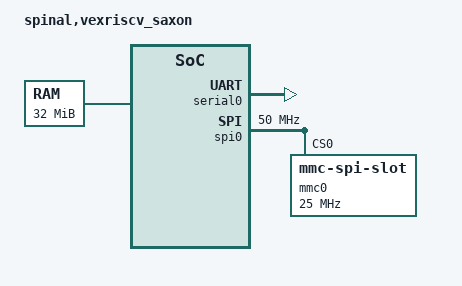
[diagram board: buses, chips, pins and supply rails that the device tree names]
/dts-v1/;

#include <config.h>

/ {
  #address-cells = <1>;
  #size-cells = <1>;
  compatible = "spinal,vexriscv";
  model = "spinal,vexriscv_saxon";

  aliases {
    serial0 = &serial0;
    timer0 = &timer0;
    spi0 = &spi0;
    mmc0 = &mmc0;
  };

  chosen {
    bootargs = "console=ttyS0,115200n8";
    stdout-path = "serial0:115200n8";
    tick-timer = "timer0";
  };

  cpus {
    #address-cells = <1>;
    #size-cells = <0>;
    timebase-frequency = <50000000>;

    cpu@0 {
      device_type = "cpu";
      compatible = "riscv";
      riscv,isa = "rv32im";
      clock-frequency = <50000000>;
      mmu-type = "riscv,sv32";
      reg = <0>;
      i-cache-size = <0x1000>;
      i-cache-line-size = <32>;
      d-cache-size = <0x1000>;
      d-cache-line-size = <32>;
      intc0: interrupt-controller {
          #interrupt-cells = <1>;
          interrupt-controller;
          compatible = "riscv,cpu-intc";
      };
    };
  };

  memory {
    device_type = "memory";
    reg = <0x80000000 0x02000000>;
  };

  timer0: timer@10008000 {
    compatible = "vexriscv,timer";
    reg = <0x10008000 0x10>;
    clock-frequency = <50000000>;
  };

  serial0: serial@10010000 {
    device_type = "serial";
    compatible = "vexriscv,uart";
    reg = <0x10010000 0x10>;
    clock-frequency = <50000000>;
  };

  spi0: spi@10020000 {
    compatible = "vexriscv,spi";
    #address-cells = <1>;
    #size-cells = <0>;
    reg = <0x10020000 0x1000>;
    cmd_fifo_depth = <256>;
    rsp_fifo_depth = <256>;
    num-cs = <1>;
    cs-gpios = <0>;
    clock-frequency = <50000000>;
    mmc0: mmc@0 {
      compatible = "mmc-spi-slot";
      reg = <0>;
      spi-max-frequency = <25000000>;
    };
  };
};
